AUTOSAR XML (schema 00046)
package /VehicleProject
  system System
    system mapping System_MPPNG
      data-mappings:
        data-element=VcuRxMsg1_Sig0.VcuRxMsg1_Sig0, system-signal=VcuRxMsg1_Sig0
        data-element=VcuRxMsg1_Sig2.VcuRxMsg1_Sig2, system-signal=VcuRxMsg1_Sig2
        data-element=VcuRxMsg1_Sig1.VcuRxMsg1_Sig1, system-signal=VcuRxMsg1_Sig1
        data-element=VcuRxMsg2_Sig3.VcuRxMsg2_Sig3, system-signal=VcuRxMsg2_Sig3
        data-element=VcuRxMsg1_Sig3.VcuRxMsg1_Sig3, system-signal=VcuRxMsg1_Sig3
        data-element=VcuRxMsg2_Sig0.VcuRxMsg2_Sig0, system-signal=VcuRxMsg2_Sig0
        data-element=VcuRxMsg2_Sig2.VcuRxMsg2_Sig2, system-signal=VcuRxMsg2_Sig2
        data-element=VcuRxMsg2_Sig1.VcuRxMsg2_Sig1, system-signal=VcuRxMsg2_Sig1
        data-element=VcuTxMsg1_Sig1.VcuTxMsg1_Sig1, system-signal=VcuTxMsg1_Sig1
        data-element=VcuTxMsg2_Sig1.VcuTxMsg2_Sig1, system-signal=VcuTxMsg2_Sig1
        data-element=VcuTxMsg2_Sig2.VcuTxMsg2_Sig2, system-signal=VcuTxMsg2_Sig2
        data-element=VcuTxMsg1_Sig3.VcuTxMsg1_Sig3, system-signal=VcuTxMsg1_Sig3
        data-element=VcuTxMsg2_Sig0.VcuTxMsg2_Sig0, system-signal=VcuTxMsg2_Sig0
        data-element=VcuTxMsg2_Sig3.VcuTxMsg2_Sig3, system-signal=VcuTxMsg2_Sig3
        data-element=VcuTxMsg1_Sig2.VcuTxMsg1_Sig2, system-signal=VcuTxMsg1_Sig2
        data-element=VcuTxMsg1_Sig0.VcuTxMsg1_Sig0, system-signal=VcuTxMsg1_Sig0
        data-element=EXT1_Valid.EXT1_Valid, system-signal=EXT1_Valid
        data-element=EXT3_Valid.EXT3_Valid, system-signal=EXT3_Valid
        data-element=EXT_A_IN4.EXT_A_IN4, system-signal=EXT_A_IN4
        data-element=EXT2_Valid.EXT2_Valid, system-signal=EXT2_Valid
        data-element=EXT4_Valid.EXT4_Valid, system-signal=EXT4_Valid
        data-element=EXT_A_IN{1..3}.EXT_A_IN{1..3}, system-signal=EXT_A_IN{1..3}
        data-element=EXT10_Valid.EXT10_Valid, system-signal=EXT10_Valid
        data-element=EXT12_Valid.EXT12_Valid, system-signal=EXT12_Valid
        data-element=EXT15_Valid.EXT15_Valid, system-signal=EXT15_Valid
        data-element=EXT5_Valid.EXT5_Valid, system-signal=EXT5_Valid
        data-element=EXT_A_IN15.EXT_A_IN15, system-signal=EXT_A_IN15
        data-element=EXT7_Valid.EXT7_Valid, system-signal=EXT7_Valid
        data-element=EXT_A_IN13.EXT_A_IN13, system-signal=EXT_A_IN13
        data-element=EXT_A_IN5.EXT_A_IN5, system-signal=EXT_A_IN5
        data-element=EXT6_Valid.EXT6_Valid, system-signal=EXT6_Valid
        data-element=EXT_A_IN12.EXT_A_IN12, system-signal=EXT_A_IN12
        data-element=EXT_A_IN7.EXT_A_IN7, system-signal=EXT_A_IN7
        data-element=EXT13_Valid.EXT13_Valid, system-signal=EXT13_Valid
        data-element=EXT_A_IN9.EXT_A_IN9, system-signal=EXT_A_IN9
        data-element=EXT9_Valid.EXT9_Valid, system-signal=EXT9_Valid
        data-element=EXT8_Valid.EXT8_Valid, system-signal=EXT8_Valid
        data-element=EXT11_Valid.EXT11_Valid, system-signal=EXT11_Valid
        data-element=EXT_A_IN6.EXT_A_IN6, system-signal=EXT_A_IN6
        data-element=EXT16_Valid.EXT16_Valid, system-signal=EXT16_Valid
        data-element=EXT14_Valid.EXT14_Valid, system-signal=EXT14_Valid
        data-element=EXT_A_IN16.EXT_A_IN16, system-signal=EXT_A_IN16
        data-element=EXT_A_IN11.EXT_A_IN11, system-signal=EXT_A_IN11
        data-element=EXT_A_IN8.EXT_A_IN8, system-signal=EXT_A_IN8
        data-element=EXT_A_IN14.EXT_A_IN14, system-signal=EXT_A_IN14
        data-element=EXT_A_IN10.EXT_A_IN10, system-signal=EXT_A_IN10
        data-element=ECC_PMP2_SpdSet.ECC_PMP2_SpdSet, system-signal=ECC_PMP2_SpdSet
        data-element=ECC_PMP3_SpdSet.ECC_PMP3_SpdSet, system-signal=ECC_PMP3_SpdSet
    root-software-compositions:
      root sw composition prototype EcuSwComposition: software-composition=ECU_Composition
package /ECUCompositionTypes
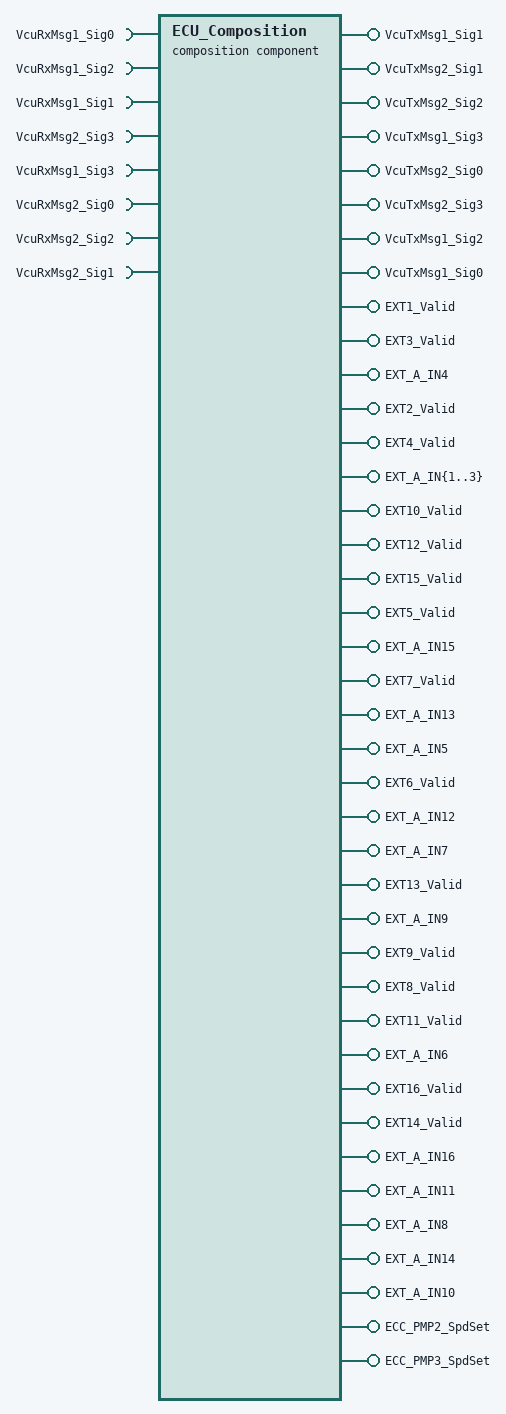
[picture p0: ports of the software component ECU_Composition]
  composition sw component type ECU_Composition
    8 x require port:
      VcuRxMsg1_Sig0: nonqueued-receiver-com-spec{data-element=VcuRxMsg1_Sig0, init-value=0}, required-interface=VcuRxMsg1_Sig0
      VcuRxMsg1_Sig2: nonqueued-receiver-com-spec{data-element=VcuRxMsg1_Sig2, init-value=0}, required-interface=VcuRxMsg1_Sig2
      VcuRxMsg1_Sig1: nonqueued-receiver-com-spec{data-element=VcuRxMsg1_Sig1, init-value=0}, required-interface=VcuRxMsg1_Sig1
      VcuRxMsg2_Sig3: nonqueued-receiver-com-spec{data-element=VcuRxMsg2_Sig3, init-value=0}, required-interface=VcuRxMsg2_Sig3
      VcuRxMsg1_Sig3: nonqueued-receiver-com-spec{data-element=VcuRxMsg1_Sig3, init-value=0}, required-interface=VcuRxMsg1_Sig3
      VcuRxMsg2_Sig0: nonqueued-receiver-com-spec{data-element=VcuRxMsg2_Sig0, init-value=0}, required-interface=VcuRxMsg2_Sig0
      VcuRxMsg2_Sig2: nonqueued-receiver-com-spec{data-element=VcuRxMsg2_Sig2, init-value=0}, required-interface=VcuRxMsg2_Sig2
      VcuRxMsg2_Sig1: nonqueued-receiver-com-spec{data-element=VcuRxMsg2_Sig1, init-value=0}, required-interface=VcuRxMsg2_Sig1
    42 x provide port:
      VcuTxMsg1_Sig1: nonqueued-sender-com-spec{data-element=VcuTxMsg1_Sig1, init-value=0}, provided-interface=VcuTxMsg1_Sig1
      VcuTxMsg2_Sig1: nonqueued-sender-com-spec{data-element=VcuTxMsg2_Sig1, init-value=0}, provided-interface=VcuTxMsg2_Sig1
      VcuTxMsg2_Sig2: nonqueued-sender-com-spec{data-element=VcuTxMsg2_Sig2, init-value=0}, provided-interface=VcuTxMsg2_Sig2
      VcuTxMsg1_Sig3: nonqueued-sender-com-spec{data-element=VcuTxMsg1_Sig3, init-value=0}, provided-interface=VcuTxMsg1_Sig3
      VcuTxMsg2_Sig0: nonqueued-sender-com-spec{data-element=VcuTxMsg2_Sig0, init-value=0}, provided-interface=VcuTxMsg2_Sig0
      VcuTxMsg2_Sig3: nonqueued-sender-com-spec{data-element=VcuTxMsg2_Sig3, init-value=0}, provided-interface=VcuTxMsg2_Sig3
      VcuTxMsg1_Sig2: nonqueued-sender-com-spec{data-element=VcuTxMsg1_Sig2, init-value=0}, provided-interface=VcuTxMsg1_Sig2
      VcuTxMsg1_Sig0: nonqueued-sender-com-spec{data-element=VcuTxMsg1_Sig0, init-value=0}, provided-interface=VcuTxMsg1_Sig0
      EXT1_Valid: nonqueued-sender-com-spec{data-element=EXT1_Valid, init-value=0}, provided-interface=EXT1_Valid
      EXT3_Valid: nonqueued-sender-com-spec{data-element=EXT3_Valid, init-value=0}, provided-interface=EXT3_Valid
      EXT_A_IN4: nonqueued-sender-com-spec{data-element=EXT_A_IN4, init-value=0}, provided-interface=EXT_A_IN4
      EXT2_Valid: nonqueued-sender-com-spec{data-element=EXT2_Valid, init-value=0}, provided-interface=EXT2_Valid
      EXT4_Valid: nonqueued-sender-com-spec{data-element=EXT4_Valid, init-value=0}, provided-interface=EXT4_Valid
      EXT_A_IN{1..3}: nonqueued-sender-com-spec{data-element=EXT_A_IN{1..3}, init-value=0}, provided-interface=EXT_A_IN{1..3}
      EXT10_Valid: nonqueued-sender-com-spec{data-element=EXT10_Valid, init-value=0}, provided-interface=EXT10_Valid
      EXT12_Valid: nonqueued-sender-com-spec{data-element=EXT12_Valid, init-value=0}, provided-interface=EXT12_Valid
      EXT15_Valid: nonqueued-sender-com-spec{data-element=EXT15_Valid, init-value=0}, provided-interface=EXT15_Valid
      EXT5_Valid: nonqueued-sender-com-spec{data-element=EXT5_Valid, init-value=0}, provided-interface=EXT5_Valid
      EXT_A_IN15: nonqueued-sender-com-spec{data-element=EXT_A_IN15, init-value=0}, provided-interface=EXT_A_IN15
      EXT7_Valid: nonqueued-sender-com-spec{data-element=EXT7_Valid, init-value=0}, provided-interface=EXT7_Valid
      EXT_A_IN13: nonqueued-sender-com-spec{data-element=EXT_A_IN13, init-value=0}, provided-interface=EXT_A_IN13
      EXT_A_IN5: nonqueued-sender-com-spec{data-element=EXT_A_IN5, init-value=0}, provided-interface=EXT_A_IN5
      EXT6_Valid: nonqueued-sender-com-spec{data-element=EXT6_Valid, init-value=0}, provided-interface=EXT6_Valid
      EXT_A_IN12: nonqueued-sender-com-spec{data-element=EXT_A_IN12, init-value=0}, provided-interface=EXT_A_IN12
      EXT_A_IN7: nonqueued-sender-com-spec{data-element=EXT_A_IN7, init-value=0}, provided-interface=EXT_A_IN7
      EXT13_Valid: nonqueued-sender-com-spec{data-element=EXT13_Valid, init-value=0}, provided-interface=EXT13_Valid
      EXT_A_IN9: nonqueued-sender-com-spec{data-element=EXT_A_IN9, init-value=0}, provided-interface=EXT_A_IN9
      EXT9_Valid: nonqueued-sender-com-spec{data-element=EXT9_Valid, init-value=0}, provided-interface=EXT9_Valid
      EXT8_Valid: nonqueued-sender-com-spec{data-element=EXT8_Valid, init-value=0}, provided-interface=EXT8_Valid
      EXT11_Valid: nonqueued-sender-com-spec{data-element=EXT11_Valid, init-value=0}, provided-interface=EXT11_Valid
      EXT_A_IN6: nonqueued-sender-com-spec{data-element=EXT_A_IN6, init-value=0}, provided-interface=EXT_A_IN6
      EXT16_Valid: nonqueued-sender-com-spec{data-element=EXT16_Valid, init-value=0}, provided-interface=EXT16_Valid
      EXT14_Valid: nonqueued-sender-com-spec{data-element=EXT14_Valid, init-value=0}, provided-interface=EXT14_Valid
      EXT_A_IN16: nonqueued-sender-com-spec{data-element=EXT_A_IN16, init-value=0}, provided-interface=EXT_A_IN16
      EXT_A_IN11: nonqueued-sender-com-spec{data-element=EXT_A_IN11, init-value=0}, provided-interface=EXT_A_IN11
      EXT_A_IN8: nonqueued-sender-com-spec{data-element=EXT_A_IN8, init-value=0}, provided-interface=EXT_A_IN8
      EXT_A_IN14: nonqueued-sender-com-spec{data-element=EXT_A_IN14, init-value=0}, provided-interface=EXT_A_IN14
      EXT_A_IN10: nonqueued-sender-com-spec{data-element=EXT_A_IN10, init-value=0}, provided-interface=EXT_A_IN10
      ECC_PMP2_SpdSet: nonqueued-sender-com-spec{data-element=ECC_PMP2_SpdSet, init-value=0}, provided-interface=ECC_PMP2_SpdSet
      ECC_PMP3_SpdSet: nonqueued-sender-com-spec{data-element=ECC_PMP3_SpdSet, init-value=0}, provided-interface=ECC_PMP3_SpdSet
    8 x component:
      SWC1: type=SWC1
      PowerMng_SWC: type=PowerMng_SWC
      Com_SWC: type=Com_SWC
      NvM_SWC: type=NvM_SWC
      DIAG_SWC: type=DIAG_SWC
      IoHwAb_SWC: type=IoHwAb_SWC
      Core2App_SWC: type=Core2App_SWC
      Core1App_SWC: type=Core1App_SWC
    delegate Com_SWC.VcuRxMsg1_Sig0 <-> outer port VcuRxMsg1_Sig0
    delegate Com_SWC.VcuRxMsg1_Sig2 <-> outer port VcuRxMsg1_Sig2
    delegate Com_SWC.VcuRxMsg1_Sig1 <-> outer port VcuRxMsg1_Sig1
    delegate Com_SWC.VcuRxMsg2_Sig3 <-> outer port VcuRxMsg2_Sig3
    delegate Com_SWC.VcuRxMsg1_Sig3 <-> outer port VcuRxMsg1_Sig3
    delegate Com_SWC.VcuRxMsg2_Sig0 <-> outer port VcuRxMsg2_Sig0
    delegate Com_SWC.VcuRxMsg2_Sig2 <-> outer port VcuRxMsg2_Sig2
    delegate Com_SWC.VcuRxMsg2_Sig1 <-> outer port VcuRxMsg2_Sig1
    delegate Com_SWC.VcuTxMsg1_Sig1 <-> outer port VcuTxMsg1_Sig1
    delegate Com_SWC.VcuTxMsg2_Sig1 <-> outer port VcuTxMsg2_Sig1
    delegate Com_SWC.VcuTxMsg2_Sig2 <-> outer port VcuTxMsg2_Sig2
    delegate Com_SWC.VcuTxMsg1_Sig3 <-> outer port VcuTxMsg1_Sig3
    delegate Com_SWC.VcuTxMsg2_Sig0 <-> outer port VcuTxMsg2_Sig0
    delegate Com_SWC.VcuTxMsg2_Sig3 <-> outer port VcuTxMsg2_Sig3
    delegate Com_SWC.VcuTxMsg1_Sig2 <-> outer port VcuTxMsg1_Sig2
    delegate Com_SWC.VcuTxMsg1_Sig0 <-> outer port VcuTxMsg1_Sig0
    connect NvM_SWC.NvM_Data_IF_UserData1_Send -> SWC1.NvM_Data_IF_UserData1_Recv
    connect SWC1.NvSWC_NvMNotifyJobFinished_UserData1 -> NvM_SWC.NvSWC_NvMNotifyJobFinished_NVBlockDescriptor_UserData1
    connect SWC1.NvM_Data_IF_UserData1_Send -> NvM_SWC.NvM_Data_IF_UserData1_Recv
    connect SWC1.NvM_Data_IF_UserData2_Send -> NvM_SWC.NvM_Data_IF_UserData2_Rcev
    connect NvM_SWC.NvM_Data_IF_UserData2_Send -> SWC1.NvM_Data_IF_UserData2_Recv
    connect SWC1.NvSWC_NvMNotifyJobFinished_UserData2 -> NvM_SWC.NvSWC_NvMNotifyJobFinished_NVBlockDescriptor_UserData2
    connect NvM_SWC.NvMService_NVBlockDescriptor_UserData2 -> SWC1.NvSWC_UserData2_NvMService_AC3_SRBS
    delegate Com_SWC.EXT1_Valid <-> outer port EXT1_Valid
    delegate Com_SWC.EXT3_Valid <-> outer port EXT3_Valid
    delegate Com_SWC.EXT_A_IN4 <-> outer port EXT_A_IN4
    delegate Com_SWC.EXT2_Valid <-> outer port EXT2_Valid
    delegate Com_SWC.EXT4_Valid <-> outer port EXT4_Valid
    delegate Com_SWC.EXT_A_IN{1..3} <-> outer port EXT_A_IN{1..3}
    delegate Com_SWC.EXT10_Valid <-> outer port EXT10_Valid
    delegate Com_SWC.EXT12_Valid <-> outer port EXT12_Valid
    delegate Com_SWC.EXT15_Valid <-> outer port EXT15_Valid
    delegate Com_SWC.EXT5_Valid <-> outer port EXT5_Valid
    delegate Com_SWC.EXT_A_IN15 <-> outer port EXT_A_IN15
    delegate Com_SWC.EXT7_Valid <-> outer port EXT7_Valid
    delegate Com_SWC.EXT_A_IN13 <-> outer port EXT_A_IN13
    delegate Com_SWC.EXT_A_IN5 <-> outer port EXT_A_IN5
    delegate Com_SWC.EXT6_Valid <-> outer port EXT6_Valid
    delegate Com_SWC.EXT_A_IN12 <-> outer port EXT_A_IN12
    delegate Com_SWC.EXT_A_IN7 <-> outer port EXT_A_IN7
    delegate Com_SWC.EXT13_Valid <-> outer port EXT13_Valid
    delegate Com_SWC.EXT_A_IN9 <-> outer port EXT_A_IN9
    delegate Com_SWC.EXT9_Valid <-> outer port EXT9_Valid
    delegate Com_SWC.EXT8_Valid <-> outer port EXT8_Valid
    delegate Com_SWC.EXT11_Valid <-> outer port EXT11_Valid
    delegate Com_SWC.EXT_A_IN6 <-> outer port EXT_A_IN6
    delegate Com_SWC.EXT16_Valid <-> outer port EXT16_Valid
    delegate Com_SWC.EXT14_Valid <-> outer port EXT14_Valid
    delegate Com_SWC.EXT_A_IN16 <-> outer port EXT_A_IN16
    delegate Com_SWC.EXT_A_IN11 <-> outer port EXT_A_IN11
    delegate Com_SWC.EXT_A_IN8 <-> outer port EXT_A_IN8
    delegate Com_SWC.EXT_A_IN14 <-> outer port EXT_A_IN14
    delegate Com_SWC.EXT_A_IN10 <-> outer port EXT_A_IN10
    delegate Com_SWC.ECC_PMP2_SpdSet <-> outer port ECC_PMP2_SpdSet
    delegate Com_SWC.ECC_PMP3_SpdSet <-> outer port ECC_PMP3_SpdSet
    connect IoHwAb_SWC.P_Arry8Bytes -> Core1App_SWC.P_Arry8Bytes
package /EndToEndProtections
  end to end protection set EndToEndProtectionSet
